# f2838x_cm_conf_regs register map
Vendor: Texas Instruments
Peripheral module from a debugger description file (folder C2000).
Address unit: 16 bits
Registers are 32-bit, read-write, no defined reset value unless marked. A register's access mark holds for its fields unless they carry their own. Offsets are as the file gives them; lines under a group give offsets from that group; [hi:lo] are bit positions; {n}, {i} and the like mark numbered series; 'fields as' and 'values as' point back to an identical list; <NAME> marks a mode.

## CM_CONF_REGS — CM CONF Registers
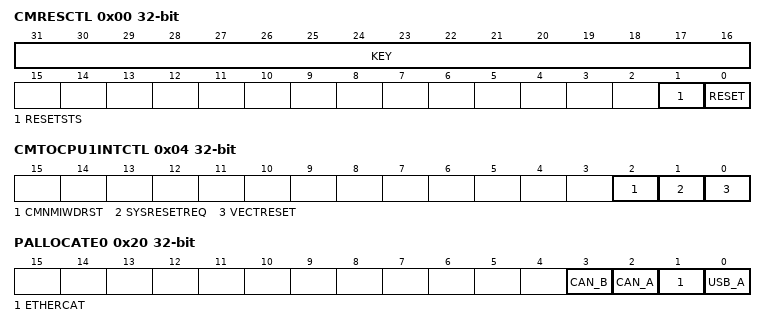
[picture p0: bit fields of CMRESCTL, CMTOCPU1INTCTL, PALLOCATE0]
0x00 CMRESCTL access per field — CM Reset Control Register
  [31:16] KEY rw — Key value
  [1] RESETSTS ro — CM Reset status
  [0] RESET rw — Software reset to CM
0x02 CMTOCPU1NMICTL — CM To CPU1 NMI Control register
  [2] CMNMIWDRST — CMNMIWDRST NMI enable bit, enables nmi generation to C28x
0x04 CMTOCPU1INTCTL — CM To CPU1 interrupt Control register
  [2] CMNMIWDRST — CMNMIWDRST Interrupt enable bit, enables interrupt to C28x
  [1] SYSRESETREQ — SYSRESETREQ Interrupt enable bit, enables interrupt to C28x
  [0] VECTRESET — VECTRESET Interrupt enable bit, enables interrupt to C28x
0x20 PALLOCATE0 — CM Peripheral Allocation Register.
  [3] CAN_B — Allocate CANB to CM
  [2] CAN_A — Allocate CANA to CM
  [1] ETHERCAT — Allocate ETHERCAT to CM
  [0] USB_A — Allocate USB_A to CM
0x3FE CM_CONF_REGS_LOCK — CM Configuration Registers Lock
  [0] LOCK — Lock one time CM configuration registers.
